AUTOSAR XML (schema 00051)
package /Components
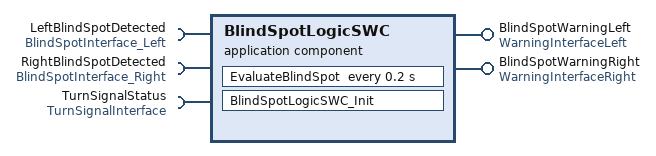
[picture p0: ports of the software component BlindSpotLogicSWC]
  application sw component type BlindSpotLogicSWC
    require port LeftBlindSpotDetected: nonqueued-receiver-com-spec{data-element=detected, init-value=0}, required-interface=BlindSpotInterface_Left
    require port RightBlindSpotDetected: nonqueued-receiver-com-spec{data-element=detected, init-value=0}, required-interface=BlindSpotInterface_Right
    require port TurnSignalStatus: nonqueued-receiver-com-spec{data-element=turn, init-value=NONE}, required-interface=TurnSignalInterface
    provide port BlindSpotWarningLeft: nonqueued-sender-com-spec{data-element=warning, init-value=0}, provided-interface=WarningInterfaceLeft
    provide port BlindSpotWarningRight: nonqueued-sender-com-spec{data-element=warning, init-value=0}, provided-interface=WarningInterfaceRight
    behavior BlindSpotLogicSWC_IB: handle-termination-and-restart=NO-SUPPORT
      timing event Timer: start-on-event=EvaluateBlindSpot, period=0.2
      init event Event: start-on-event=BlindSpotLogicSWC_Init
      runnable EvaluateBlindSpot
        data-read-access:
          access IN_LeftBlindSpotDetected_detected: accessed-variable=LeftBlindSpotDetected.detected
          access IN_RightBlindSpotDetected_detected: accessed-variable=RightBlindSpotDetected.detected
          access IN_TurnSignalStatus_turn: accessed-variable=TurnSignalStatus.turn
        data-write-access:
          access OUT_BlindSpotWarningLeft_warning: accessed-variable=BlindSpotWarningLeft.warning
          access OUT_BlindSpotWarningRight_warning: accessed-variable=BlindSpotWarningRight.warning
      runnable BlindSpotLogicSWC_Init
